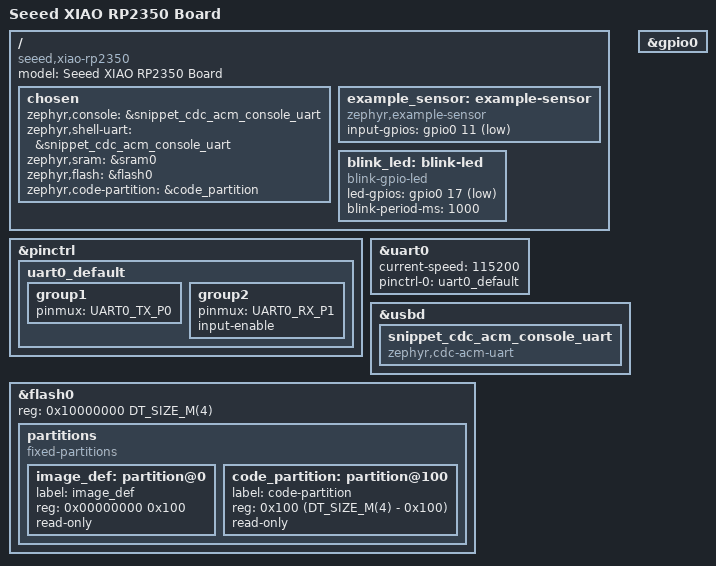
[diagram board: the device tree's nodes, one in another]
/*
 * Copyright (c) 2021 Nordic Semiconductor ASA
 * SPDX-License-Identifier: Apache-2.0
 */

/dts-v1/;
#include <raspberrypi/rpi_pico/rp2350a.dtsi>
#include <raspberrypi/rpi_pico/m33.dtsi>
// #include "xiao_rp2350-pinctrl.dtsi"
#include <zephyr/dt-bindings/pinctrl/rpi-pico-rp2350a-pinctrl.h>

/ {
	model = "Seeed XIAO RP2350 Board";
	compatible = "seeed,xiao-rp2350";

	chosen {
		zephyr,console = &snippet_cdc_acm_console_uart;
                zephyr,shell-uart = &snippet_cdc_acm_console_uart;
		zephyr,sram = &sram0;
		zephyr,flash = &flash0;
		zephyr,code-partition = &code_partition;
	};

	example_sensor: example-sensor {
		compatible = "zephyr,example-sensor";
		input-gpios = <&gpio0 11 (GPIO_PULL_UP | GPIO_ACTIVE_LOW)>;
	};

	blink_led: blink-led {
		compatible = "blink-gpio-led";
		led-gpios = <&gpio0 17 GPIO_ACTIVE_LOW>;
		blink-period-ms = <1000>;
	};
};


&pinctrl {
	uart0_default: uart0_default {
		group1 {
				pinmux = <UART0_TX_P0>;
		};
		group2 {
				pinmux = <UART0_RX_P1>;
				input-enable;
		};
	};
};


&uart0 {
        current-speed = <115200>;
        status = "okay";
        pinctrl-0 = <&uart0_default>;
        pinctrl-names = "default";
};

zephyr_udc0: &usbd {
	status = "okay";
	snippet_cdc_acm_console_uart: snippet_cdc_acm_console_uart {
		compatible = "zephyr,cdc-acm-uart";
	};
};



&gpio0 {
        status = "okay";
};

&flash0 {
        reg = <0x10000000 DT_SIZE_M(4)>;

        partitions {
                compatible = "fixed-partitions";
                #address-cells = <1>;
                #size-cells = <1>;

                /* Reserved memory for an image definition block. The block is much
                 * smaller than 256 bytes, but in practice the linker places the vector
                 * table at a much larger alignment offset.
                 */
                image_def: partition@0 {
                        label = "image_def";
                        reg = <0x00000000 0x100>;
                        read-only;
                };

                /*
                 * Usable flash. Starts at 0x100, after the image definition block.
                 * The partition size is 4MB minus the 0x100 bytes taken by the
                 * image definition.
                 */
                code_partition: partition@100 {
                        label = "code-partition";
                        reg = <0x100 (DT_SIZE_M(4) - 0x100)>;
                        read-only;
                };
        };
};
